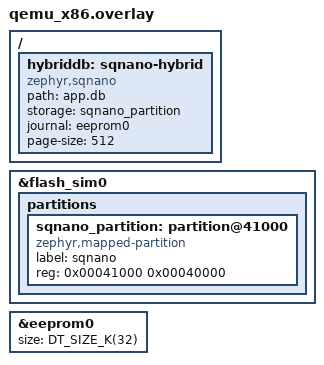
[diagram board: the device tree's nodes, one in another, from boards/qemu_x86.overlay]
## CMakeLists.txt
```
# Copyright (c) 2026 Romain Pelletant
# SPDX-License-Identifier: Apache-2.0

cmake_minimum_required(VERSION 3.20.0)

set(SQNANO_ROOT ${CMAKE_CURRENT_LIST_DIR}/../../..)
list(APPEND EXTRA_ZEPHYR_MODULES ${SQNANO_ROOT})

find_package(Zephyr REQUIRED HINTS $ENV{ZEPHYR_BASE})
project(sqnano_hybrid_test)

target_sources(app PRIVATE src/main.c)
zephyr_sqnano_queries(${SQNANO_ROOT}/tests/host/app/queries.sql
  SCHEMA ${SQNANO_ROOT}/tests/host/app/schema
  EXTRACT src/main.c
  WRAPPERS count:2)
```

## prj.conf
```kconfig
CONFIG_ZTEST=y
CONFIG_ZTEST_STACK_SIZE=16384

CONFIG_FLASH=y
CONFIG_FLASH_MAP=y
CONFIG_FLASH_SIMULATOR=y
CONFIG_FLASH_SIMULATOR_STATS=y
CONFIG_STATS=y
CONFIG_EEPROM=y
CONFIG_EEPROM_SIMULATOR=y

CONFIG_SQNANO=y
CONFIG_SQNANO_PROFILE_STANDARD=y
CONFIG_SQNANO_MAX_PAGE_SIZE=512
CONFIG_SQNANO_HYBRID_MAX_ERASES=256
```

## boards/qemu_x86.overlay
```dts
/*
 * Copyright (c) 2026 Romain Pelletant
 * SPDX-License-Identifier: Apache-2.0
 */

/* A flash partition behind the EEPROM simulator used as a FRAM. */

&flash_sim0 {
	partitions {
		sqnano_partition: partition@41000 {
			compatible = "zephyr,mapped-partition";
			label = "sqnano";
			reg = <0x00041000 0x00040000>;
		};
	};
};

&eeprom0 {
	size = <DT_SIZE_K(32)>;
};

/ {
	hybriddb: sqnano-hybrid {
		compatible = "zephyr,sqnano";
		path = "app.db";
		storage = <&sqnano_partition>;
		journal = <&eeprom0>;
		page-size = <512>;
	};
};
```

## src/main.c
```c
/*
 * Copyright (c) 2026 Romain Pelletant
 * SPDX-License-Identifier: Apache-2.0
 */

/*
 * Hybrid mode on the flash and EEPROM simulators: one row per commit, then
 * the database read back after closing it; the flash erases stay rare.
 */

#include <zephyr/ztest.h>

#include <sqlite3.h>
#include <sqnano/zephyr.h>

static int count(sqlite3 *c, const char *sql)
{
	sqlite3_stmt *st;
	int n = -1;

	zassert_ok(sqlite3_prepare_v2(c, sql, -1, &st, NULL), "%s", sqlite3_errmsg(c));
	if (sqlite3_step(st) == SQLITE_ROW) {
		n = sqlite3_column_int(st, 0);
	}
	sqlite3_finalize(st);
	return n;
}

ZTEST(sqnano_hybrid, test_commits_and_reopen)
{
	const struct sqnano_dt_db *d = sqnano_dt_find("app.db");
	struct sqnano_hybrid_zmedia *zm;
	sqlite3 *c = NULL;
	sqlite3_stmt *st;

	zassert_not_null(d);
	zm = CONTAINER_OF(d->media, struct sqnano_hybrid_zmedia, hy.media);
	zassert_ok(sqlite3_open("app.db", &c), "%s", sqlite3_errmsg(c));
	zassert_ok(sqlite3_prepare_v2(c, "INSERT INTO sensor (id, ts, value) VALUES (:id, :ts, :value)",
				      -1, &st, NULL));
	for (int i = 0; i < 400; i++) {
		/* Autocommit: one commit per row. */
		sqlite3_bind_int(st, 1, i % 4);
		sqlite3_bind_int64(st, 2, 9000 + i);
		sqlite3_bind_double(st, 3, i * 0.25);
		zassert_equal(sqlite3_step(st), SQLITE_DONE, "%s", sqlite3_errmsg(c));
		sqlite3_reset(st);
	}
	sqlite3_finalize(st);
	zassert_ok(sqlite3_exec(c, "DELETE FROM sensor WHERE ts < 9100", NULL, NULL, NULL));
	zassert_equal(count(c, "SELECT count(*) FROM sensor"), 300);
	TC_PRINT("hybrid: 400 commits, %u flash erases, %u flash programs, %u evictions, "
		 "%u erases kept in FRAM\n",
		 zm->hy.flash_erases, zm->hy.flash_programs, zm->hy.evictions,
		 zm->hy.virtual_erases);
	/* The table grows, so its pages reach the flash; the hot ones do not. */
	zassert_true(zm->hy.flash_erases < 400 && zm->hy.virtual_erases > zm->hy.flash_erases,
		     "the FRAM should absorb most erases");
	zassert_ok(sqlite3_close(c));

	/* Closed, then mounted again from the flash and the FRAM. */
	zassert_ok(sqnano_db_close(d->db));
	zassert_ok(sqlite3_open("app.db", &c));
	zassert_equal(count(c, "SELECT count(*) FROM sensor WHERE id = 2"), 75);
	zassert_ok(sqnano_db_check(sqnano_sqlite3_db(c)));
	zassert_ok(sqlite3_close(c));
}

ZTEST_SUITE(sqnano_hybrid, NULL, NULL, NULL, NULL, NULL);
```
